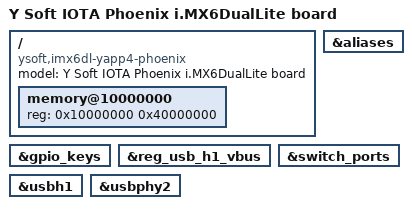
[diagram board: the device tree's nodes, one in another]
// SPDX-License-Identifier: GPL-2.0
//
// Copyright (C) 2021 Y Soft Corporation, a.s.

/dts-v1/;

#include "imx6dl.dtsi"
#include "imx6dl-yapp43-common.dtsi"

/ {
	model = "Y Soft IOTA Phoenix i.MX6DualLite board";
	compatible = "ysoft,imx6dl-yapp4-phoenix", "fsl,imx6dl";

	memory@10000000 {
		device_type = "memory";
		reg = <0x10000000 0x40000000>;
	};
};

&aliases {
	/delete-property/ ethernet1;
};

&gpio_keys {
	status = "okay";
};

&reg_usb_h1_vbus {
	status = "okay";
};

&switch_ports {
	/delete-node/ port@2;
};

&usbh1 {
	status = "okay";
};

&usbphy2 {
	status = "okay";
};
